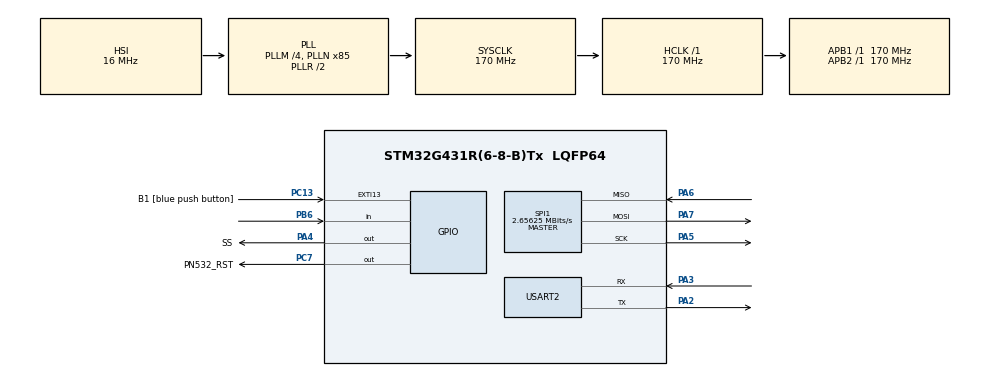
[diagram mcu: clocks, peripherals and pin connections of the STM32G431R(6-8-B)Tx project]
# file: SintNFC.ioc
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Mcu.Family=STM32G4
Mcu.Name=STM32G431R(6-8-B)Tx
Mcu.Package=LQFP64
NVIC.PriorityGroup=NVIC_PRIORITYGROUP_4
NVIC.TIM6_DAC_IRQn=true\:0\:0\:false\:false\:true\:true\:true
PA13.GPIO_Label=T_SWDIO
PA13.Mode=Serial_Wire
PA13.Signal=SYS_JTMS-SWDIO
PA14.GPIO_Label=T_SWCLK
PA14.Mode=Serial_Wire
PA14.Signal=SYS_JTCK-SWCLK
PA2.Mode=Asynchronous
PA2.Signal=USART2_TX
PA3.Mode=Asynchronous
PA3.Signal=USART2_RX
PA4.GPIO_Label=SS
PA4.PinState=GPIO_PIN_SET
PA4.Signal=GPIO_Output
PA5.Mode=Full_Duplex_Master
PA5.Signal=SPI1_SCK
PA6.GPIO_PuPd=GPIO_PULLUP
PA6.Mode=Full_Duplex_Master
PA6.Signal=SPI1_MISO
PA7.Mode=Full_Duplex_Master
PA7.Signal=SPI1_MOSI
PB3.GPIO_Label=T_SWO
PB3.Signal=SYS_JTDO-SWO
PB6.Signal=GPIO_Input
PC13.GPIO_Label=B1 [blue push button]
PC13.Signal=GPXTI13
PC14-OSC32_IN.Mode=LSE-External-Oscillator
PC14-OSC32_IN.Signal=RCC_OSC32_IN
PC15-OSC32_OUT.Mode=LSE-External-Oscillator
PC15-OSC32_OUT.Signal=RCC_OSC32_OUT
PC7.GPIO_Label=PN532_RST
PC7.Signal=GPIO_Output
PF0-OSC_IN.Mode=HSE-External-Oscillator
PF0-OSC_IN.Signal=RCC_OSC_IN
PF1-OSC_OUT.Mode=HSE-External-Oscillator
PF1-OSC_OUT.Signal=RCC_OSC_OUT
ProjectManager.HeapSize=0x200
ProjectManager.StackSize=0x400
ProjectManager.TargetToolchain=STM32CubeIDE
RCC.ADC12Freq_Value=170000000
RCC.AHBFreq_Value=170000000
RCC.APB1Freq_Value=170000000
RCC.APB1TimFreq_Value=170000000
RCC.APB2Freq_Value=170000000
RCC.APB2TimFreq_Value=170000000
RCC.CK48CLockSelection=RCC_USBCLKSOURCE_HSI48
RCC.CortexFreq_Value=170000000
RCC.EXTERNAL_CLOCK_VALUE=12288000
RCC.HCLKFreq_Value=170000000
RCC.HSE_VALUE=24000000
RCC.HSI48_VALUE=48000000
RCC.HSI_VALUE=16000000
RCC.PLLM=RCC_PLLM_DIV4
RCC.PLLN=85
RCC.RTCClockSelection=RCC_RTCCLKSOURCE_LSE
RCC.SYSCLKFreq_VALUE=170000000
RCC.SYSCLKSource=RCC_SYSCLKSOURCE_PLLCLK
RCC.USBFreq_Value=48000000
RCC.VCOOutputFreq_Value=340000000
SPI1.BaudRatePrescaler=SPI_BAUDRATEPRESCALER_64
SPI1.CLKPhase=SPI_PHASE_1EDGE
SPI1.CLKPolarity=SPI_POLARITY_HIGH
SPI1.CalculateBaudRate=2.65625 MBits/s
SPI1.DataSize=SPI_DATASIZE_8BIT
SPI1.Direction=SPI_DIRECTION_2LINES
SPI1.FirstBit=SPI_FIRSTBIT_LSB
SPI1.Mode=SPI_MODE_MASTER
SPI1.VirtualType=VM_MASTER
TIM6.PeriodNoDither=10000
TIM6.Prescaler=170
USART2.VirtualMode-Asynchronous=VM_ASYNC
VP_RNG_VS_RNG.Mode=RNG_Activate
VP_SYS_VS_DBSignals.Mode=DisableDeadBatterySignals
VP_TIM6_VS_ClockSourceINT.Mode=Enable_Timer
board=NUCLEO-G431RB

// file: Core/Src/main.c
/* USER CODE BEGIN Header */
/**
  ******************************************************************************
  * @file           : main.c
  * @brief          : Main program body
  ******************************************************************************
  * @attention
  *
  * <h2><center>&copy; Copyright (c) 2021 STMicroelectronics.
  * All rights reserved.</center></h2>
  *
  * This software component is licensed by ST under BSD 3-Clause license,
  * the "License"; You may not use this file except in compliance with the
  * License. You may obtain a copy of the License at:
  *                        opensource.org/licenses/BSD-3-Clause
  *
  ******************************************************************************
  */
/* USER CODE END Header */
#include "main.h"

RNG_HandleTypeDef hrng;

SPI_HandleTypeDef hspi1;

TIM_HandleTypeDef htim6;

UART_HandleTypeDef huart2;

void SystemClock_Config(void);
static void MX_GPIO_Init(void);
static void MX_SPI1_Init(void);
static void MX_USART2_UART_Init(void);
static void MX_RNG_Init(void);
static void MX_TIM6_Init(void);

int main(void)
{

  /* MCU Configuration--------------------------------------------------------*/

  /* Reset of all peripherals, Initializes the Flash interface and the Systick. */
  HAL_Init();

  /* Configure the system clock */
  SystemClock_Config();

  /* Initialize all configured peripherals */
  MX_GPIO_Init();
  MX_SPI1_Init();
  MX_USART2_UART_Init();
  MX_RNG_Init();
  MX_TIM6_Init();
  /* USER CODE BEGIN 2 */
  NFC_Init();
  NFC_InitializeBufs();

  /* USER CODE END 2 */

  /* Infinite loop */
  /* USER CODE BEGIN WHILE */
  while (1)
  {
	  NFC_MainLoop();
    /* USER CODE END WHILE */

  }
}

void SystemClock_Config(void)
{
  RCC_OscInitTypeDef RCC_OscInitStruct = {0};
  RCC_ClkInitTypeDef RCC_ClkInitStruct = {0};
  RCC_PeriphCLKInitTypeDef PeriphClkInit = {0};

  /** Configure the main internal regulator output voltage
  */
  HAL_PWREx_ControlVoltageScaling(PWR_REGULATOR_VOLTAGE_SCALE1_BOOST);
  /** Initializes the RCC Oscillators according to the specified parameters
  * in the RCC_OscInitTypeDef structure.
  */
  RCC_OscInitStruct.OscillatorType = RCC_OSCILLATORTYPE_HSI|RCC_OSCILLATORTYPE_HSI48;
  RCC_OscInitStruct.HSIState = RCC_HSI_ON;
  RCC_OscInitStruct.HSICalibrationValue = RCC_HSICALIBRATION_DEFAULT;
  RCC_OscInitStruct.HSI48State = RCC_HSI48_ON;
  RCC_OscInitStruct.PLL.PLLState = RCC_PLL_ON;
  RCC_OscInitStruct.PLL.PLLSource = RCC_PLLSOURCE_HSI;
  RCC_OscInitStruct.PLL.PLLM = RCC_PLLM_DIV4;
  RCC_OscInitStruct.PLL.PLLN = 85;
  RCC_OscInitStruct.PLL.PLLP = RCC_PLLP_DIV2;
  RCC_OscInitStruct.PLL.PLLQ = RCC_PLLQ_DIV2;
  RCC_OscInitStruct.PLL.PLLR = RCC_PLLR_DIV2;
  if (HAL_RCC_OscConfig(&RCC_OscInitStruct) != HAL_OK)
  {
    Error_Handler();
  }
  /** Initializes the CPU, AHB and APB buses clocks
  */
  RCC_ClkInitStruct.ClockType = RCC_CLOCKTYPE_HCLK|RCC_CLOCKTYPE_SYSCLK
                              |RCC_CLOCKTYPE_PCLK1|RCC_CLOCKTYPE_PCLK2;
  RCC_ClkInitStruct.SYSCLKSource = RCC_SYSCLKSOURCE_PLLCLK;
  RCC_ClkInitStruct.AHBCLKDivider = RCC_SYSCLK_DIV1;
  RCC_ClkInitStruct.APB1CLKDivider = RCC_HCLK_DIV1;
  RCC_ClkInitStruct.APB2CLKDivider = RCC_HCLK_DIV1;

  if (HAL_RCC_ClockConfig(&RCC_ClkInitStruct, FLASH_LATENCY_4) != HAL_OK)
  {
    Error_Handler();
  }
  /** Initializes the peripherals clocks
  */
  PeriphClkInit.PeriphClockSelection = RCC_PERIPHCLK_USART2|RCC_PERIPHCLK_RNG;
  PeriphClkInit.Usart2ClockSelection = RCC_USART2CLKSOURCE_PCLK1;
  PeriphClkInit.RngClockSelection = RCC_RNGCLKSOURCE_HSI48;
  if (HAL_RCCEx_PeriphCLKConfig(&PeriphClkInit) != HAL_OK)
  {
    Error_Handler();
  }
}

static void MX_RNG_Init(void)
{

  hrng.Instance = RNG;
  hrng.Init.ClockErrorDetection = RNG_CED_ENABLE;
  if (HAL_RNG_Init(&hrng) != HAL_OK)
  {
    Error_Handler();
  }

}

static void MX_SPI1_Init(void)
{

  /* SPI1 parameter configuration*/
  hspi1.Instance = SPI1;
  hspi1.Init.Mode = SPI_MODE_MASTER;
  hspi1.Init.Direction = SPI_DIRECTION_2LINES;
  hspi1.Init.DataSize = SPI_DATASIZE_8BIT;
  hspi1.Init.CLKPolarity = SPI_POLARITY_HIGH;
  hspi1.Init.CLKPhase = SPI_PHASE_1EDGE;
  hspi1.Init.NSS = SPI_NSS_SOFT;
  hspi1.Init.BaudRatePrescaler = SPI_BAUDRATEPRESCALER_64;
  hspi1.Init.FirstBit = SPI_FIRSTBIT_LSB;
  hspi1.Init.TIMode = SPI_TIMODE_DISABLE;
  hspi1.Init.CRCCalculation = SPI_CRCCALCULATION_DISABLE;
  hspi1.Init.CRCPolynomial = 7;
  hspi1.Init.CRCLength = SPI_CRC_LENGTH_DATASIZE;
  hspi1.Init.NSSPMode = SPI_NSS_PULSE_ENABLE;
  if (HAL_SPI_Init(&hspi1) != HAL_OK)
  {
    Error_Handler();
  }

}

static void MX_TIM6_Init(void)
{

  TIM_MasterConfigTypeDef sMasterConfig = {0};

  htim6.Instance = TIM6;
  htim6.Init.Prescaler = 170;
  htim6.Init.CounterMode = TIM_COUNTERMODE_UP;
  htim6.Init.Period = 10000;
  htim6.Init.AutoReloadPreload = TIM_AUTORELOAD_PRELOAD_DISABLE;
  if (HAL_TIM_Base_Init(&htim6) != HAL_OK)
  {
    Error_Handler();
  }
  sMasterConfig.MasterOutputTrigger = TIM_TRGO_RESET;
  sMasterConfig.MasterSlaveMode = TIM_MASTERSLAVEMODE_DISABLE;
  if (HAL_TIMEx_MasterConfigSynchronization(&htim6, &sMasterConfig) != HAL_OK)
  {
    Error_Handler();
  }

}

static void MX_USART2_UART_Init(void)
{

  huart2.Instance = USART2;
  huart2.Init.BaudRate = 115200;
  huart2.Init.WordLength = UART_WORDLENGTH_8B;
  huart2.Init.StopBits = UART_STOPBITS_1;
  huart2.Init.Parity = UART_PARITY_NONE;
  huart2.Init.Mode = UART_MODE_TX_RX;
  huart2.Init.HwFlowCtl = UART_HWCONTROL_NONE;
  huart2.Init.OverSampling = UART_OVERSAMPLING_16;
  huart2.Init.OneBitSampling = UART_ONE_BIT_SAMPLE_DISABLE;
  huart2.Init.ClockPrescaler = UART_PRESCALER_DIV1;
  huart2.AdvancedInit.AdvFeatureInit = UART_ADVFEATURE_NO_INIT;
  if (HAL_UART_Init(&huart2) != HAL_OK)
  {
    Error_Handler();
  }
  if (HAL_UARTEx_SetTxFifoThreshold(&huart2, UART_TXFIFO_THRESHOLD_1_8) != HAL_OK)
  {
    Error_Handler();
  }
  if (HAL_UARTEx_SetRxFifoThreshold(&huart2, UART_RXFIFO_THRESHOLD_1_8) != HAL_OK)
  {
    Error_Handler();
  }
  if (HAL_UARTEx_DisableFifoMode(&huart2) != HAL_OK)
  {
    Error_Handler();
  }

}

static void MX_GPIO_Init(void)
{
  GPIO_InitTypeDef GPIO_InitStruct = {0};

  /* GPIO Ports Clock Enable */
  __HAL_RCC_GPIOC_CLK_ENABLE();
  __HAL_RCC_GPIOF_CLK_ENABLE();
  __HAL_RCC_GPIOA_CLK_ENABLE();
  __HAL_RCC_GPIOB_CLK_ENABLE();

  /*Configure GPIO pin Output Level */
  HAL_GPIO_WritePin(SS_GPIO_Port, SS_Pin, GPIO_PIN_SET);

  /*Configure GPIO pin Output Level */
  HAL_GPIO_WritePin(PN532_RST_GPIO_Port, PN532_RST_Pin, GPIO_PIN_RESET);

  /*Configure GPIO pin : B1_Pin */
  GPIO_InitStruct.Pin = B1_Pin;
  GPIO_InitStruct.Mode = GPIO_MODE_IT_RISING;
  GPIO_InitStruct.Pull = GPIO_NOPULL;
  HAL_GPIO_Init(B1_GPIO_Port, &GPIO_InitStruct);

  /*Configure GPIO pin : SS_Pin */
  GPIO_InitStruct.Pin = SS_Pin;
  GPIO_InitStruct.Mode = GPIO_MODE_OUTPUT_PP;
  GPIO_InitStruct.Pull = GPIO_NOPULL;
  GPIO_InitStruct.Speed = GPIO_SPEED_FREQ_LOW;
  HAL_GPIO_Init(SS_GPIO_Port, &GPIO_InitStruct);

  /*Configure GPIO pin : PN532_RST_Pin */
  GPIO_InitStruct.Pin = PN532_RST_Pin;
  GPIO_InitStruct.Mode = GPIO_MODE_OUTPUT_PP;
  GPIO_InitStruct.Pull = GPIO_NOPULL;
  GPIO_InitStruct.Speed = GPIO_SPEED_FREQ_LOW;
  HAL_GPIO_Init(PN532_RST_GPIO_Port, &GPIO_InitStruct);

  /*Configure GPIO pin : PB6 */
  GPIO_InitStruct.Pin = GPIO_PIN_6;
  GPIO_InitStruct.Mode = GPIO_MODE_INPUT;
  GPIO_InitStruct.Pull = GPIO_NOPULL;
  HAL_GPIO_Init(GPIOB, &GPIO_InitStruct);

}

void Error_Handler(void)
{
  __disable_irq();
  while (1)
  {
  }
}

/************************ (C) COPYRIGHT STMicroelectronics *****END OF FILE****/
